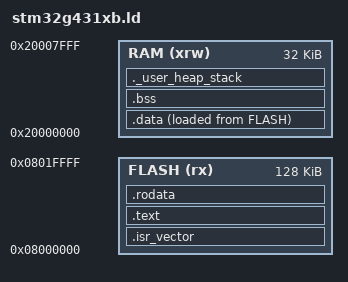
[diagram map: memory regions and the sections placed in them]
/*
 * Linker script for STM32G431K8 (128KB Flash, 32KB SRAM)
 * Architecture: ARM Cortex-M4F
 */

ENTRY(Reset_Handler)

_estack = ORIGIN(RAM) + LENGTH(RAM);

_Min_Heap_Size = 0x0;      /* Zero heap allocation (safety-critical policy) */
_Min_Stack_Size = 0x800;   /* 2 KB reserved for deterministic call stack */

MEMORY
{
  RAM   (xrw) : ORIGIN = 0x20000000, LENGTH = 32K
  FLASH (rx)  : ORIGIN = 0x08000000, LENGTH = 128K
}

SECTIONS
{
  /* ISR vector table at Flash start */
  .isr_vector :
  {
    . = ALIGN(4);
    KEEP(*(.isr_vector))
    . = ALIGN(4);
  } >FLASH

  /* Executable code and inlined constants */
  .text :
  {
    . = ALIGN(4);
    *(.text)
    *(.text*)
    *(.glue_7)
    *(.glue_7t)
    *(.eh_frame)

    KEEP (*(.init))
    KEEP (*(.fini))

    . = ALIGN(4);
    _etext = .;
  } >FLASH

  /* Read-only data */
  .rodata :
  {
    . = ALIGN(4);
    *(.rodata)
    *(.rodata*)
    . = ALIGN(4);
  } >FLASH

  /* Initialized data copied into RAM at startup */
  _sidata = LOADADDR(.data);

  .data : 
  {
    . = ALIGN(4);
    _sdata = .;
    *(.data)
    *(.data*)
    . = ALIGN(4);
    _edata = .;
  } >RAM AT> FLASH

  /* Uninitialized data zero-filled at startup */
  .bss :
  {
    . = ALIGN(4);
    _sbss = .;
    __bss_start__ = _sbss;
    *(.bss)
    *(.bss*)
    *(COMMON)
    . = ALIGN(4);
    _ebss = .;
    __bss_end__ = _ebss;
  } >RAM

  /* Stack boundary check */
  ._user_heap_stack :
  {
    . = ALIGN(8);
    PROVIDE ( end = . );
    PROVIDE ( _end = . );
    . = . + _Min_Heap_Size;
    . = . + _Min_Stack_Size;
    . = ALIGN(8);
  } >RAM

  /DISCARD/ :
  {
    libc.a ( * )
    libm.a ( * )
    libgcc.a ( * )
  }
}
